AUTOSAR XML (schema 314)
package /ComponentType
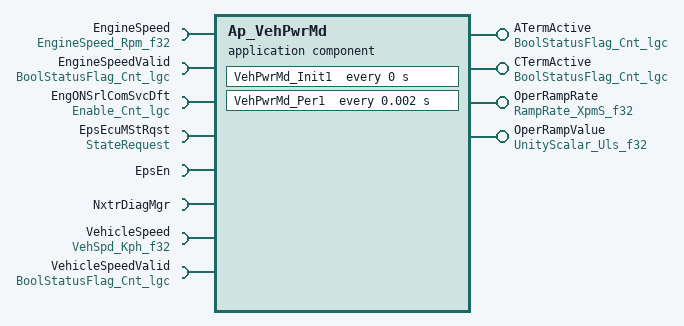
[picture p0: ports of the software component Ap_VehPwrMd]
  application software component type Ap_VehPwrMd
    4 x provide port:
      ATermActive: unqueued-sender-com-spec{data-element=Cnt_lgc, can-invalidate=false, init-value=D_TRUE_CNT_LGC}, provided-interface=BoolStatusFlag_Cnt_lgc
      CTermActive: unqueued-sender-com-spec{data-element=Cnt_lgc, can-invalidate=false, init-value=D_FALSE_CNT_LGC}, provided-interface=BoolStatusFlag_Cnt_lgc
      OperRampRate: unqueued-sender-com-spec{data-element=XpmS_f32, can-invalidate=false, init-value=D_ZERO_ULS_F32}, provided-interface=RampRate_XpmS_f32
      OperRampValue: unqueued-sender-com-spec{data-element=Uls_f32, can-invalidate=false, init-value=D_ZERO_ULS_F32}, provided-interface=UnityScalar_Uls_f32
    8 x require port:
      EngineSpeed: unqueued-receiver-com-spec{data-element=Rpm_f32, init-value=D_ZERO_ULS_F32}, required-interface=EngineSpeed_Rpm_f32
      EngineSpeedValid: unqueued-receiver-com-spec{data-element=Cnt_lgc, init-value=D_FALSE_CNT_LGC}, required-interface=BoolStatusFlag_Cnt_lgc
      EngONSrlComSvcDft: unqueued-receiver-com-spec{data-element=Cnt_lgc, init-value=D_FALSE_CNT_LGC}, required-interface=Enable_Cnt_lgc
      EpsEcuMStRqst: required-com-specs=[GetState, ReleasePOSTRUN, ReleaseRUN, RequestPOSTRUN, RequestRUN], required-interface=StateRequest
      EpsEn: client-com-spec=OP_GET, required-interface=EpsEn
      NxtrDiagMgr: required-com-specs=[GetNTCActive, GetNTCFailed, GetNTCStatus, SetNTCStatus], required-interface=NxtrDiagMgr
      VehicleSpeed: unqueued-receiver-com-spec{data-element=Kph_f32, init-value=D_ZERO_ULS_F32}, required-interface=VehSpd_Kph_f32
      VehicleSpeedValid: unqueued-receiver-com-spec{data-element=Cnt_lgc, init-value=D_FALSE_CNT_LGC}, required-interface=BoolStatusFlag_Cnt_lgc
  internal behavior Ap_VehPwrMd_InternalBehavior: component=Ap_VehPwrMd
    timing event VehPwrMd_Init1_InitEvent: start-on-event=VehPwrMd_Init1, period=0
    timing event TMT_VehPwrMd_Per1: start-on-event=VehPwrMd_Per1, period=0.002
    port-api-options:
      enable-take-address=false, indirect-api=false, port=ATermActive
      enable-take-address=false, indirect-api=false, port=CTermActive
      enable-take-address=false, indirect-api=false, port=EngineSpeed
      enable-take-address=false, indirect-api=false, port=EngineSpeedValid
      enable-take-address=false, indirect-api=false, port=EngONSrlComSvcDft
      enable-take-address=false, indirect-api=false, port=EpsEcuMStRqst
      enable-take-address=false, indirect-api=false, port=EpsEn
      enable-take-address=false, indirect-api=false, port=NxtrDiagMgr
      enable-take-address=false, indirect-api=false, port=OperRampRate
      enable-take-address=false, indirect-api=false, port=OperRampValue
      enable-take-address=false, indirect-api=false, port=VehicleSpeed
      enable-take-address=false, indirect-api=false, port=VehicleSpeedValid
    runnable VehPwrMd_Init1
      data write access WRITE_OperRampRate_XpmS_f32: data-element=OperRampRate.XpmS_f32
      data write access WRITE_OperRampValue_Uls_f32: data-element=OperRampValue.Uls_f32
    runnable VehPwrMd_Per1
      5 x data read access:
        READ_EngineSpeed_Rpm_f32: data-element=EngineSpeed.Rpm_f32
        READ_EngineSpeedValid_Cnt_lgc: data-element=EngineSpeedValid.Cnt_lgc
        READ_EngONSrlComSvcDft_Cnt_lgc: data-element=EngONSrlComSvcDft.Cnt_lgc
        READ_VehicleSpeed_Kph_f32: data-element=VehicleSpeed.Kph_f32
        READ_VehicleSpeedValid_Cnt_lgc: data-element=VehicleSpeedValid.Cnt_lgc
      4 x data write access:
        WRITE_ATermActive_Cnt_lgc: data-element=ATermActive.Cnt_lgc
        WRITE_CTermActive_Cnt_lgc: data-element=CTermActive.Cnt_lgc
        WRITE_OperRampRate_XpmS_f32: data-element=OperRampRate.XpmS_f32
        WRITE_OperRampValue_Uls_f32: data-element=OperRampValue.Uls_f32
      sync call SC_EpsEn_OP_GET: operation=EpsEn.OP_GET, timeout=0
      sync call SC_NxtrDiagMgr_GetNTCActive: operation=NxtrDiagMgr.GetNTCActive, timeout=0
  swc implementation Ap_VehPwrMd_Implementation: behavior=Ap_VehPwrMd_InternalBehavior
    code-descriptors:
      code Code: type=SRC
